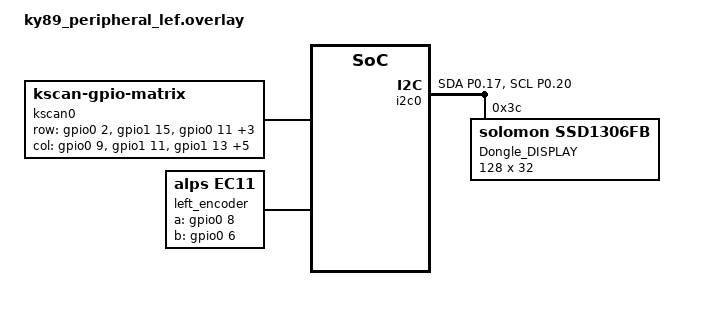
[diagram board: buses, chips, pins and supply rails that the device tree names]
/*
 * Copyright (c) 2023 The ZMK Contributors
 *
 * SPDX-License-Identifier: MIT
 */

#include "ky89.dtsi"

&pinctrl {
    i2c0_default: i2c0_default {
        group1 {
            psels = <NRF_PSEL(TWIM_SDA, 0, 17)>,
                    <NRF_PSEL(TWIM_SCL, 0, 20)>;
        };
    };

    i2c0_sleep: i2c0_sleep {
        group1 {
            psels = <NRF_PSEL(TWIM_SDA, 0, 17)>,
                    <NRF_PSEL(TWIM_SCL, 0, 20)>;
            low-power-enable;
        };
    };
};

&i2c0 {
	status = "okay";
	//compatible = "nordic,nrf-twi";
	pinctrl-0 = <&i2c0_default>;
	pinctrl-1 = <&i2c0_sleep>;
	pinctrl-names = "default", "sleep";
    
	oled: ssd1306@3c {
        // 分辨率修改
        width = <128>;
		height = <32>;

        // 0.91或0.96，使用以下
        compatible = "solomon,ssd1306fb";   //0.91   0.96
        segment-offset = <0>;   //0.91   0.96
        multiplex-ratio = <31>; //128*32
        com-sequential; //1.30注销本行
        
        // 1.30，使用以下
        //compatible = "sinowealth,sh1106";   //1.30
        //segment-offset = <2>;   //1.30
		//multiplex-ratio = <63>; //128*64
        
		reg = <0x3c>;
		label = "Dongle_DISPLAY";
		page-offset = <0>;
		display-offset = <0>;
		segment-remap;
		com-invdir;
        inversion-on;   // 翻转颜色
		prechargep = <0x22>;
        
	};
};

/ {
    chosen {
        zmk,kscan = &kscan0;
        zephyr,display = &oled;
    };

    kscan0: kscan {
        compatible = "zmk,kscan-gpio-matrix";
        wakeup-source;

        diode-direction = "col2row";

        row-gpios
            = <&gpio0  2 (GPIO_PULL_DOWN | GPIO_ACTIVE_HIGH)>
            , <&gpio1 15 (GPIO_PULL_DOWN | GPIO_ACTIVE_HIGH)>
            , <&gpio0 11 (GPIO_PULL_DOWN | GPIO_ACTIVE_HIGH)>
            , <&gpio1  0 (GPIO_PULL_DOWN | GPIO_ACTIVE_HIGH)>
            , <&gpio0 24 (GPIO_PULL_DOWN | GPIO_ACTIVE_HIGH)>
            , <&gpio0 22 (GPIO_PULL_DOWN | GPIO_ACTIVE_HIGH)>
            ;

        col-gpios
            = <&gpio0  9 GPIO_ACTIVE_HIGH>
            , <&gpio1 11 GPIO_ACTIVE_HIGH>
            , <&gpio1 13 GPIO_ACTIVE_HIGH>
            , <&gpio0 29 GPIO_ACTIVE_HIGH>
            , <&gpio0 31 GPIO_ACTIVE_HIGH>
            , <&gpio1  6 GPIO_ACTIVE_HIGH>
            , <&gpio1  4 GPIO_ACTIVE_HIGH>
            , <&gpio0 10 GPIO_ACTIVE_HIGH>
            ;
    };

    left_encoder: left_encoder {
        compatible = "alps,ec11";
        steps = <80>;
        a-gpios = <&gpio0  8 (GPIO_ACTIVE_HIGH | GPIO_PULL_UP)>;
        b-gpios = <&gpio0  6 (GPIO_ACTIVE_HIGH | GPIO_PULL_UP)>;
        status = "okay";
    };

    sensors: sensors {
        compatible = "zmk,keymap-sensors";
        sensors = <&left_encoder>;
        triggers-per-rotation = <20>;
    };
};




